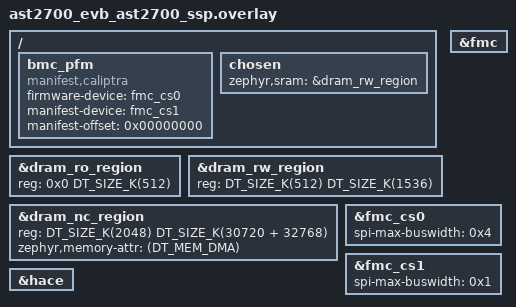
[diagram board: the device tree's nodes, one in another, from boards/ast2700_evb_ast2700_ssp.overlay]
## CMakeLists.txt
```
# Copyright (c) 2026 ASPEED Technology Inc.
# SPDX-License-Identifier: MIT

cmake_minimum_required(VERSION 3.20.0)
find_package(Zephyr REQUIRED HINTS $ENV{ZEPHYR_BASE})
project(aspeed_irot)

zephyr_compile_options(-std=c11)

zephyr_include_directories(.)
zephyr_include_directories(src)

add_subdirectory(src)
```

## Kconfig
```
# Copyright (c) 2026 ASPEED Technology Inc.
# SPDX-License-Identifier: MIT

config IROT_PSP_RESET
	bool "PSP reset detection"
	depends on DT_HAS_ASPEED_AST2700_SSP_PSP_RESET_NOTIFY_ENABLED
	select PSP_RESET_NOTIFY_ASPEED
	default n
	help
	  Enable PSP reset detection. After the CA35 is released, the iRoT
	  arms the PSP reset notification interrupt; when the PSP resets,
	  a RESET_DETECTED event is sent to the iRoT state machine, which
	  moves back to VERIFY to re-verify and reload the PSP images.

rsource "Kconfig.cptra"
rsource "Kconfig.spdm"
rsource "Kconfig.pldm"
rsource "Kconfig.composite_eat"
source "Kconfig.zephyr"
```

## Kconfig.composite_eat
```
# Copyright (c) 2026 ASPEED Technology Inc.
# SPDX-License-Identifier: MIT

config COMPOSITE_EAT
	bool "Composite EAT"
	select BMC_COMPOSITE_EAT_SDK
	default n
	help
	  Enable Composite EAT (Entity Attestation Token) generation. The iRoT
	  acts as the Lead Attester: it collects local evidence from Caliptra,
	  builds the signed main token with the BMC Composite EAT SDK, and
	  serves it over MCTP VDM-PCI. Disabling this drops the token builder,
	  the evidence and attestation providers, and the VDM-PCI message type.
```

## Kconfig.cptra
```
config ATF_LOAD_ADDR
	default 0
	hex "Address in memory for ATF firmware"
	help
	  Address in memory to use as the default safe load address for ATF.

config OPTEE_LOAD_ADDR
	default 0
	hex "Address in memory for OPTEE firmware"
	help
	  Address in memory to use as the default safe load address for OPTEE.

config UBOOT_LOAD_ADDR
	default 0
	hex "Address in memory for UBOOT firmware"
	help
	  Address in memory to use as the default safe load address for UBOOT.

config TSP_LOAD_ADDR
	default 0
	hex "Address in memory for TSP firmware"
	help
	  Address in memory to use as the default safe load address for TSP.

config KERNEL_LOAD_ADDR
	default 0
	hex "Address in memory for Kernel firmware"
	help
	  Address in memory to use as the default safe load address for Kernel.

config SKIP_CPTRA_FW_VERIFICATION
	default n
	bool "Skip firmware verification"
	help
	  If enabled, the firmware will be loaded without verification. This option is reserved for emulator environment.
```

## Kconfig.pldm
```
# Copyright (c) 2026 ASPEED Technology Inc.
# SPDX-License-Identifier: MIT

config PLDM
	bool "PLDM"
	default n
	help
	  Platform Level Data Model (PLDM) is a standard for managing and monitoring platform components. It provides a common interface for communication between management controllers and platform components, enabling efficient and standardized management of hardware resources. Enabling PLDM support allows the system to utilize PLDM features for improved hardware management and monitoring capabilities.

if PLDM

config PLDM_BASE
	bool "PLDM Base"
	default n
	help
	  The PLDM Base component provides the core functionality for the Platform Level Data Model (PLDM). It includes the essential features and interfaces required for PLDM communication and management. Enabling PLDM Base allows the system to utilize the fundamental capabilities of PLDM for efficient hardware management and monitoring.

config PLDM_FW_UPDATE
	bool "PLDM Firmware Update"
	default n
	help
	  The PLDM Firmware Update component enables support for firmware updates using the Platform Level Data Model (PLDM). It allows the system to perform firmware updates on platform components through PLDM communication, providing a standardized and efficient method for managing firmware across various hardware resources.

config PLDM_OEM
	bool "PLDM OEM"
	default n
	help
	  The PLDM OEM component provides support for OEM-specific extensions to the Platform Level Data Model (PLDM). It allows manufacturers to implement custom features and functionalities that are not covered by the standard PLDM specification, enabling enhanced management and monitoring capabilities tailored to specific hardware platforms.
endif
```

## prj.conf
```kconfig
CONFIG_DEBUG_INFO=y
CONFIG_DEBUG_THREAD_INFO=y
# CONFIG_STACK_SENTINEL=y
CONFIG_MEM_ATTR=y
CONFIG_MULTI_HEAP=y
CONFIG_SHARED_MULTI_HEAP=y
# CONFIG_STACK_CANARIES=y
# CONFIG_SPEED_OPTIMIZATIONS=y

CONFIG_SHELL=y
CONFIG_SHELL_STACK_SIZE=32768
# CONFIG_SHELL_BACKEND_SERIAL_INIT_PRIORITY=99
# CONFIG_SHELL_BACKEND_SERIAL_LOG_MESSAGE_QUEUE_TIMEOUT=-1
CONFIG_SHELL_BACKEND_SERIAL_LOG_MESSAGE_QUEUE_SIZE=8192
CONFIG_SHELL_ARGC_MAX=70

CONFIG_SERIAL_INIT_PRIORITY=45
CONFIG_CONSOLE_INIT_PRIORITY=45
CONFIG_LOG=y
# CONFIG_LOG_MODE_IMMEDIATE=y
CONFIG_LOG_MODE_DEFERRED=y
CONFIG_LOG_BUFFER_SIZE=8192

CONFIG_SMF=y
# CONFIG_MINIMAL_LIBC=y

CONFIG_COMMON_LIBC_MALLOC_ARENA_SIZE=524288
CONFIG_SYS_HEAP_INFO=y

CONFIG_MBEDTLS=y
CONFIG_MBEDTLS_SHA384=y
CONFIG_MBEDTLS_SHA512=y
CONFIG_MBEDTLS_ECP_C=y
CONFIG_MBEDTLS_ECDSA_C=y
CONFIG_MBEDTLS_ECP_DP_SECP384R1_ENABLED=y
CONFIG_MBEDTLS_ECP_NIST_OPTIM=y
# SPDM secure sessions (libspdm mbedTLS cryptlib): ECDHE P-384, HKDF/HMAC
# SHA-384 and AES-256-GCM. X.509/PK parsing is enabled in mbedtls_config.h.
CONFIG_MBEDTLS_ECDH_C=y
CONFIG_MBEDTLS_HKDF_C=y
CONFIG_MBEDTLS_MD=y
CONFIG_MBEDTLS_CIPHER=y
CONFIG_MBEDTLS_CIPHER_AES_ENABLED=y
CONFIG_MBEDTLS_CIPHER_GCM_ENABLED=y
CONFIG_MBEDTLS_USER_CONFIG_ENABLE=y
CONFIG_MBEDTLS_USER_CONFIG_FILE="mbedtls_config.h"

CONFIG_SPDM_RESPONDER=y
CONFIG_DMTF_LIBSPDM=y
CONFIG_DMTF_LIBSPDM_CONFIG_FILE="libspdm_config.h"
CONFIG_DMTF_LIBSPDM_OS_STUB_CRYPTLIB_MBEDTLS=y
# Caliptra holds the responder key: the app supplies libspdm_ecdsa_sign()
CONFIG_DMTF_LIBSPDM_APP_ECDSA_SIGN=y

CONFIG_PLDM=y
CONFIG_PLDM_BASE=y
CONFIG_PLDM_FW_UPDATE=y
CONFIG_PLDM_OEM=y

CONFIG_COMPOSITE_EAT=y

# Disabled by default
# CONFIG_IROT_PSP_RESET=y

# CONFIG_SKIP_CPTRA_FW_VERIFICATION=y
```

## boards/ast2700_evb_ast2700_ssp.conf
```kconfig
# CONFIG_TEST_RANDOM_GENERATOR=y
# CONFIG_CTR_DRBG_CSPRNG_GENERATOR=y

CONFIG_IPM_AST2700=y
CONFIG_IPM_AST2600=n
CONFIG_IPM_BOOTMCU=n

CONFIG_CPTRA_IPC_SSP=y

# CONFIG_DMTF_LIBSPDM_CALIPTRA_CRYPTO=y
# CONFIG_DMTF_LIBSPDM_CALIPTRA_CRYPTO_ECDSA=y

CONFIG_SYSTEM_WORKQUEUE_STACK_SIZE=4096
# CONFIG_HEAP_MEM_POOL_SIZE=8192
# CONFIG_SHELL_STACK_SIZE=4096

CONFIG_FLASH=y
CONFIG_FLASH_PAGE_LAYOUT=y
# CONFIG_FLASH_MAP=y
CONFIG_FLASH_SHELL=y
# CONFIG_FLASH_MAP_SHELL=y

CONFIG_CLOCK_CONTROL_AST27XX=y
CONFIG_CRYPTO=y
CONFIG_CRYPTO_ASPEED=y
CONFIG_HASH_SHELL=y

CONFIG_SPI=y
# CONFIG_SPI_NOR is not set
CONFIG_SPI_ASPEED=y
CONFIG_SPI_DMA_SUPPORT_ASPEED=y
CONFIG_SPI_NOR_MULTI_DEV=y
# CONFIG_SPI_LOG_LEVEL_DBG=y

# CONFIG_SERIAL_INIT_PRIORITY=45
# CONFIG_CONSOLE_INIT_PRIORITY=45
CONFIG_WATCHDOG=y
CONFIG_WDT_ASPEED=y

CONFIG_CPTRA_IPC_SSP=y


CONFIG_ATF_LOAD_ADDR=0x04000000
CONFIG_OPTEE_LOAD_ADDR=0x04080000
CONFIG_UBOOT_LOAD_ADDR=0x05880000
CONFIG_TSP_LOAD_ADDR=0x00000000
CONFIG_KERNEL_LOAD_ADDR=0x08880000

CONFIG_OTP_AST27XX=y
```

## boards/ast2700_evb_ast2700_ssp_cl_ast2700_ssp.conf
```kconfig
CONFIG_IPM_AST2700=y
CONFIG_IPM_AST2600=n
CONFIG_IPM_BOOTMCU=n

CONFIG_CPTRA_IPC_SSP=y

CONFIG_SYSTEM_WORKQUEUE_STACK_SIZE=4096

CONFIG_FLASH=y
CONFIG_FLASH_PAGE_LAYOUT=y
CONFIG_FLASH_SHELL=y

CONFIG_SPI=y
CONFIG_SPI_NOR=n
CONFIG_SPI_ASPEED=y
CONFIG_SPI_DMA_SUPPORT_ASPEED=y
CONFIG_SPI_NOR_MULTI_DEV=y

CONFIG_WATCHDOG=y
CONFIG_WDT_ASPEED=y

CONFIG_CLOCK_CONTROL_AST27XX=y

CONFIG_CRYPTO=y
CONFIG_CRYPTO_ASPEED=y
CONFIG_HASH_SHELL=y

CONFIG_BOOTLOADER_MCUBOOT=y

CONFIG_ATF_LOAD_ADDR=0x04000000
CONFIG_OPTEE_LOAD_ADDR=0x04080000
CONFIG_UBOOT_LOAD_ADDR=0x05880000
CONFIG_TSP_LOAD_ADDR=0x00000000
CONFIG_KERNEL_LOAD_ADDR=0x08880000
```

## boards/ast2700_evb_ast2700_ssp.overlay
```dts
#include <zephyr/dt-bindings/memory-attr/memory-attr-arm.h>
#include <zephyr/dt-bindings/memory-attr/memory-attr.h>

/ {
	bmc_pfm {
		compatible = "manifest,caliptra";
		firmware-device = <&fmc_cs0>;
		manifest-device = <&fmc_cs1>;
		manifest-offset = <0x00000000>;
	};

	chosen {
		zephyr,sram = &dram_rw_region;
	};
};

&dram_ro_region {
	reg = <0x0 DT_SIZE_K(512)>;
};

&dram_rw_region {
	reg = <DT_SIZE_K(512) DT_SIZE_K(1536)>;
};

&dram_nc_region {
	reg = <DT_SIZE_K(2048) DT_SIZE_K(30720 + 32768)>;
	zephyr,memory-attr = <(DT_MEM_DMA)>;
};

&fmc {
	status = "okay";
	// timing-calibration-disabled;
};

&fmc_cs0 {
	status = "okay";
	spi-max-buswidth = < 0x4 >;
};

&fmc_cs1 {
	status = "okay";
	spi-max-buswidth = < 0x1 >;
};

// &wdt4 {
// 	status = "okay";
// 	reset-mask = <0x00000000 0x00000000 0x00000000 0x00000000 0x00000000>;
// };

&hace {
	status = "okay";
};
```

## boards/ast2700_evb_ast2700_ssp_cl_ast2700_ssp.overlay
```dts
#include <zephyr/dt-bindings/memory-attr/memory-attr-arm.h>
#include <zephyr/dt-bindings/memory-attr/memory-attr.h>

/ {
	bmc_pfm {
		compatible = "manifest,caliptra";
		firmware-device = <&fmc_cs0>;
		manifest-device = <&fmc_cs1>;
		manifest-offset = <0x00000000>;
	};

	chosen {
		zephyr,sram = &dram_rw_region;
	};
};

/*
 * mcuboot occupies 0x0 - 0x7FFFF (512KB).
 * irot .text/.rodata is loaded here by mcuboot.
 */
&dram_ro_region {
	reg = <0x80000 DT_SIZE_K(512)>;
};

&dram_rw_region {
	reg = <DT_SIZE_K(512 + 512) DT_SIZE_K(1024)>;
};

&dram_nc_region {
	reg = <DT_SIZE_K(2048) DT_SIZE_K(30720 + 32768)>;
	zephyr,memory-attr = <(DT_MEM_DMA)>;
};

&fmc {
	status = "okay";
};

&fmc_cs0 {
	status = "okay";
	spi-max-buswidth = < 0x4 >;
};

&fmc_cs1 {
	status = "okay";
	spi-max-buswidth = < 0x1 >;
};

&hace {
	status = "okay";
};
```

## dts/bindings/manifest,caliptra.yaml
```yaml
description: Caliptra SoC Manifest

compatible: "manifest,caliptra"

include: [base.yaml]

properties:
  firmware-device:
    type: phandle
    required: true
  manifest-device:
    type: phandle
    required: true
  manifest-offset:
    type: int
    required: true
```

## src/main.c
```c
/*
 * Copyright (c) 2026 ASPEED Technology Inc.
 *
 * SPDX-License-Identifier: MIT
 */

#include <stdlib.h>

#include <zephyr/kernel.h>
#include <zephyr/logging/log.h>

#include <state_machine/irot_fsm.h>

LOG_MODULE_REGISTER(aspeed_irot);


// int example_generate_composite_eat(const struct example_attestation_provider *attestation_provider,
//                                    const struct example_evidence_provider *evidence_provider,
//                                    const struct composite_eat_generation_request *request,
//                                    struct composite_eat_workspace *workspace, uint8_t *response,
//                                    size_t response_capacity, size_t *response_length);

int main() {
	LOG_INF("Aspeed IROT FW Started");

	irot_send_event(START_STATE_MACHINE, NULL);

	return 0;
}

static int jtag_init(void)
{

	printk("Enable JTAG PIN Mux\n");
	uint32_t SCU0_408 = 0x72c02408;
	sys_write32(0x820, SCU0_408);

	// DEBUG_HALT();

	return 0;
}

SYS_INIT(jtag_init, EARLY, 0);


#if defined(CONFIG_SHELL)
#include <zephyr/shell/shell.h>

static int cmd_jtag_psp(const struct shell *shell, size_t argc, char **argv)
{
	shell_print(shell, "Switch to PSP for JTAG debug\n");
	uint32_t SCU0_408 = 0x72c02408;
	sys_write32(0x000, SCU0_408);
	return 0;
}

static int cmd_jtag_ssp(const struct shell *shell, size_t argc, char **argv)
{
	shell_print(shell, "Switch to SSP for JTAG debug\n");
	uint32_t SCU0_408 = 0x72c02408;
	sys_write32(0x820, SCU0_408);
	return 0;
}

static int cmd_jtag_tsp(const struct shell *shell, size_t argc, char **argv)
{
	uint32_t SCU0_408 = 0x72c02408;
	sys_write32(0x840, SCU0_408);
	return 0;
}


SHELL_STATIC_SUBCMD_SET_CREATE(sub_jtag,
	SHELL_CMD(psp, NULL, "Switch CPU for JTAG debug", cmd_jtag_psp),
	SHELL_CMD(ssp, NULL, "Switch SSP for JTAG debug", cmd_jtag_ssp),
	SHELL_CMD(tsp, NULL, "Switch TSP for JTAG debug", cmd_jtag_tsp),
	SHELL_SUBCMD_SET_END
);

SHELL_CMD_REGISTER(jtag, &sub_jtag, "Halt CPU for JTAG debug", NULL);

#include <zephyr/device.h>
#include <zephyr/drivers/flash.h>
static int cmd_flash_read(const struct shell *shell, size_t argc, char **argv)
{
	shell_print(shell, "Flash read command executed\n");

	const struct device *fmc_dev = device_get_binding(argv[1]);
	if (!fmc_dev) {
		shell_print(shell, "Failed to get %s device binding\n", argv[1]);
		return -ENODEV;
	}

	uint32_t flash_addr = strtoul(argv[2], NULL, 0);
	uint32_t ddr_addr = strtoul(argv[3], NULL, 0);
	uint32_t size = strtoul(argv[4], NULL, 0);

	int ret = flash_read(fmc_dev, flash_addr, (uint8_t *)ddr_addr, size);
	if (ret != 0) {
		shell_print(shell, "Failed to read from flash device %s at address 0x%08X\n", argv[1], flash_addr);
		return ret;
	} else {
		shell_print(shell, "Successfully read %u bytes from flash device %s at address 0x%08X to RAM address 0x%08X\n",
			size, argv[1], flash_addr, ddr_addr);
	}

	return 0;
}

#include <mbedtls/sha512.h>
static int cmd_mbedtls_sha384(const struct shell *shell, size_t argc, char **argv)
{
	shell_print(shell, "mbedtls hash command executed\n");

	uint32_t data_off = strtoul(argv[1], NULL, 0);
	uint32_t data_size = strtoul(argv[2], NULL, 0);

	mbedtls_sha512_context sha_ctx;
	mbedtls_sha512_init(&sha_ctx);
	mbedtls_sha512_starts(&sha_ctx, 1);

	mbedtls_sha512_update(&sha_ctx, (const uint8_t *)data_off, data_size);

	uint8_t hash_output[48];
	mbedtls_sha512_finish(&sha_ctx, hash_output);
	shell_print(shell, "SHA384 hash of data at 0x%08X (size %u) is:", data_off, data_size);
	shell_hexdump(shell, hash_output, sizeof(hash_output));
	mbedtls_sha512_free(&sha_ctx);

	return 0;
}

#include <zephyr/multi_heap/shared_multi_heap.h>
#include <zephyr/devicetree.h>

#define NONCACHE_NODE DT_NODELABEL(dram_nc_region)
#define NONCACHE_ADDR DT_REG_ADDR(NONCACHE_NODE)
#define NONCACHE_SIZE DT_REG_SIZE(NONCACHE_NODE)

static int cmd_multi_heap_init(const struct shell *shell, size_t argc, char **argv)
{
	shell_print(shell, "Multi-heap test command executed\n");
	
	struct shared_multi_heap_region region = {
		.addr = NONCACHE_ADDR + 1024*1024,	
		.size = NONCACHE_SIZE - 1024*1024,
		.attr = SMH_REG_ATTR_NON_CACHEABLE,
	};	

	shared_multi_heap_pool_init();
	shared_multi_heap_add(&region, NULL);

	return 0;
}

static int cmd_multi_heap_alloc(const struct shell *shell, size_t argc, char **argv)
{
	shell_print(shell, "Multi-heap alloc command executed\n");
	
	size_t alloc_size = strtoul(argv[1], NULL, 0);
	void *ptr = shared_multi_heap_alloc(SMH_REG_ATTR_NON_CACHEABLE, alloc_size);
	if (ptr) {
		shell_print(shell, "Allocated %u bytes from shared multi-heap at address 0x%08X", alloc_size, (uint32_t)ptr);
	} else {
		shell_print(shell, "Failed to allocate memory from shared multi-heap");
	}

	return 0;
}

static int cmd_multi_heap_free(const struct shell *shell, size_t argc, char **argv)
{
	shell_print(shell, "Multi-heap free command executed\n");
	
	uint32_t addr = strtoul(argv[1], NULL, 0);
	void *ptr = (void *)addr;
	shared_multi_heap_free(ptr);

	shell_print(shell, "Freed memory at address 0x%08X back to shared multi-heap", addr);

	return 0;
}

static int cmd_multi_heap_status(const struct shell *shell, size_t argc, char **argv)
{
	shell_print(shell, "Multi-heap status command executed\n");
	

	return 0;
}

SHELL_STATIC_SUBCMD_SET_CREATE(sub_test,
	SHELL_CMD_ARG(flash_read, NULL, "Read data from <device> <flash_off> <ram_addr> <size>", cmd_flash_read, 6, 0),
	SHELL_CMD_ARG(mbedtls_sha384, NULL, "Perform mbedtls hash operation", cmd_mbedtls_sha384, 3, 0),
	SHELL_CMD_ARG(multi_heap_init, NULL, "Initialize shared multi-heap pool", cmd_multi_heap_init, 1, 0),
	SHELL_CMD_ARG(multi_heap_alloc, NULL, "Allocate memory from shared multi-heap", cmd_multi_heap_alloc, 2, 0),
	SHELL_CMD_ARG(multi_heap_free, NULL, "Free memory back to shared multi-heap", cmd_multi_heap_free, 2, 0),
	SHELL_CMD_ARG(multi_heap_status, NULL, "Show shared multi-heap status", cmd_multi_heap_status, 1, 0),
	SHELL_SUBCMD_SET_END
);

SHELL_CMD_REGISTER(test, &sub_test, "test shell commands", NULL);
#endif
```
